# PIC18F26Q84 register map
Vendor: Microchip
Registers are 8-bit, read-write, reset 0x0 unless marked. A register's access mark holds for its fields unless they carry their own. Addresses are absolute, and some are shared; only a register's first bit layout is shown; [hi:lo] are bit positions; {n}, {i} and the like mark numbered series; 'fields as' and 'values as' point back to an identical list.

## tmr_smt
0x300 SMT1TMRL
  [7:0] TMR
0x301 SMT1TMRH
  [7:0] TMR
0x302 SMT1TMRU
  [7:0] TMR
0x303 SMT1CPRL ro reset not defined — (power-on value xxxxxxxx)
  [7:0] CPR
0x304 SMT1CPRH ro reset not defined — (power-on value xxxxxxxx)
  [7:0] CPR
0x305 SMT1CPRU ro reset not defined — (power-on value xxxxxxxx)
  [7:0] CPR
0x306 SMT1CPWL ro reset not defined — (power-on value xxxxxxxx)
  [7:0] CPW
0x307 SMT1CPWH ro reset not defined — (power-on value xxxxxxxx)
  [7:0] CPW
0x308 SMT1CPWU ro reset not defined — (power-on value xxxxxxxx)
  [7:0] CPW
0x309 SMT1PRL reset 0xFF
  [7:0] PR
0x30A SMT1PRH reset 0xFF
  [7:0] PR
0x30B SMT1PRU reset 0xFF
  [7:0] PR
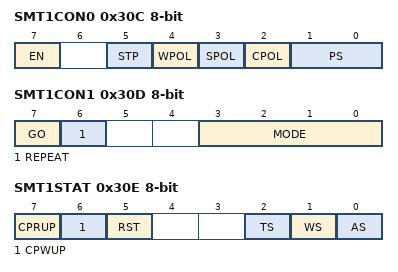
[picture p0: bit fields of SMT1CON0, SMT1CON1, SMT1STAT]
0x30C SMT1CON0
  [7] EN, [5] STP, [4] WPOL, [3] SPOL, [2] CPOL, [1:0] PS
0x30D SMT1CON1
  [7] GO, [6] REPEAT, [3:0] MODE
0x30E SMT1STAT
  [7] CPRUP, [6] CPWUP, [5] RST, [2] TS ro, [1] WS ro, [0] AS ro
0x30F SMT1CLK
  [2:0] CSEL
0x310 SMT1SIG
  [4:0] SSEL
0x311 SMT1WIN
  [4:0] WSEL

## tmr
0x318 TMR0L
0x319 TMR0H reset 0xFF
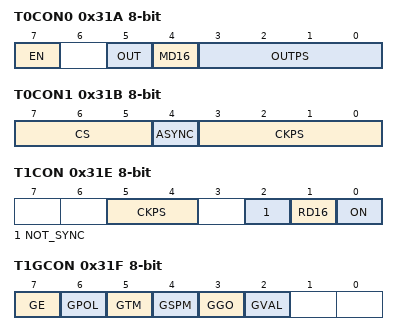
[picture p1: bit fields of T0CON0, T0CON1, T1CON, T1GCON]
0x31A T0CON0
  [7] EN, [5] OUT ro, [4] MD16, [3:0] OUTPS
0x31B T0CON1
  [7:5] CS, [4] ASYNC, [3:0] CKPS
0x31C TMR1L
0x31D TMR1H
0x31E T1CON
  [5:4] CKPS, [2] NOT_SYNC, [1] RD16, [0] ON
0x31F T1GCON reset not defined — (power-on value 00000x--)
  [7] GE, [6] GPOL, [5] GTM, [4] GSPM, [3] GGO, [2] GVAL ro
0x320 T1GATE
  [4:0] GSS
0x321 T1CLK
  [4:0] CS
0x322 T2TMR — 8-bit period timer
  [7:0] TMR2
0x323 T2PR reset 0xFF
  [7:0] PR2
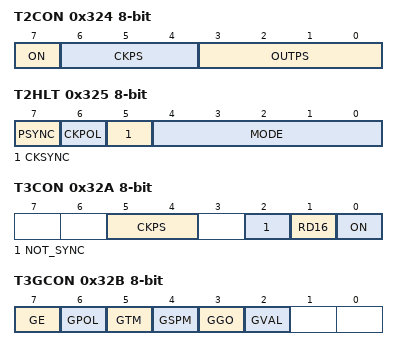
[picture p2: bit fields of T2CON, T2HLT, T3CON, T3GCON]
0x324 T2CON
  [7] ON, [6:4] CKPS, [3:0] OUTPS
0x325 T2HLT
  [7] PSYNC, [6] CKPOL, [5] CKSYNC, [4:0] MODE
0x326 T2CLKCON
  [3:0] CS
0x327 T2RST
  [4:0] RSEL
0x328 TMR3L
0x329 TMR3H
0x32A T3CON
  [5:4] CKPS, [2] NOT_SYNC, [1] RD16, [0] ON
0x32B T3GCON reset not defined — (power-on value 00000x--)
  [7] GE, [6] GPOL, [5] GTM, [4] GSPM, [3] GGO, [2] GVAL ro
0x32C T3GATE
  [4:0] GSS
0x32D T3CLK
  [4:0] CS
0x32E T4TMR — 8-bit period timer
  [7:0] TMR4
0x32F T4PR reset 0xFF
  [7:0] PR4
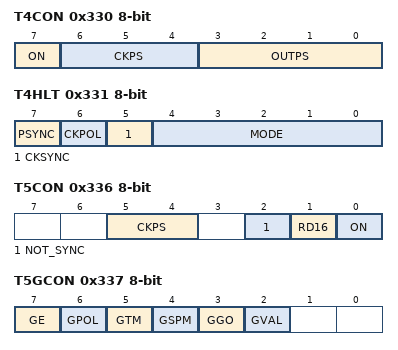
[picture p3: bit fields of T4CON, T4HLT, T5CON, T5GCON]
0x330 T4CON
  [7] ON, [6:4] CKPS, [3:0] OUTPS
0x331 T4HLT
  [7] PSYNC, [6] CKPOL, [5] CKSYNC, [4:0] MODE
0x332 T4CLKCON
  [3:0] CS
0x333 T4RST
  [4:0] RSEL
0x334 TMR5L
0x335 TMR5H
0x336 T5CON
  [5:4] CKPS, [2] NOT_SYNC, [1] RD16, [0] ON
0x337 T5GCON reset not defined — (power-on value 00000x--)
  [7] GE, [6] GPOL, [5] GTM, [4] GSPM, [3] GGO, [2] GVAL ro
0x338 T5GATE
  [4:0] GSS
0x339 T5CLK
  [4:0] CS
0x33A T6TMR — 8-bit period timer
  [7:0] TMR6
0x33B T6PR reset 0xFF
  [7:0] PR6
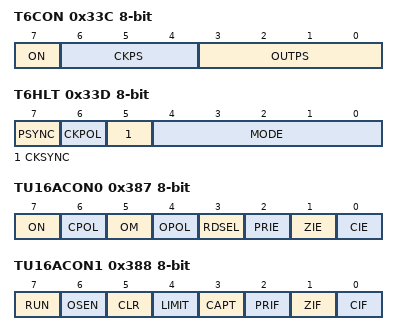
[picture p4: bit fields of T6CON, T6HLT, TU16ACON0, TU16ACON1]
0x33C T6CON
  [7] ON, [6:4] CKPS, [3:0] OUTPS
0x33D T6HLT
  [7] PSYNC, [6] CKPOL, [5] CKSYNC, [4:0] MODE
0x33E T6CLKCON
  [3:0] CS
0x33F T6RST
  [4:0] RSEL
0x387 TU16ACON0
  [7] ON, [6] CPOL, [5] OM, [4] OPOL, [3] RDSEL, [2] PRIE, [1] ZIE, [0] CIE
0x388 TU16ACON1
  [7] RUN ro, [6] OSEN, [5] CLR, [4] LIMIT, [3] CAPT, [2] PRIF, [1] ZIF, [0] CIF
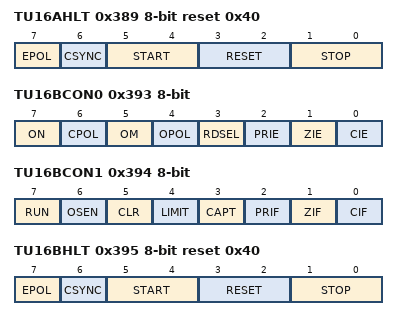
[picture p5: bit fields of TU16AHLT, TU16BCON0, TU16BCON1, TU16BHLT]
0x389 TU16AHLT reset 0x40
  [7] EPOL, [6] CSYNC, [5:4] START, [3:2] RESET, [1:0] STOP
0x38A TU16APS
  [7:0] PS
0x38D TU16APRL reset 0xFF
  [7:0] PRL
0x38E TU16APRH reset 0xFF
  [7:0] PRH
0x38F TU16ACLK
  [4:0] CLK
0x390 TU16AERS
  [5:0] ERS
0x393 TU16BCON0
  fields as TU16ACON0
0x394 TU16BCON1
  fields as TU16ACON1
0x395 TU16BHLT reset 0x40
  [7] EPOL, [6] CSYNC, [5:4] START, [3:2] RESET, [1:0] STOP
0x396 TU16BPS
  [7:0] PS
0x399 TU16BPRL reset 0xFF
  [7:0] PRL
0x39A TU16BPRH reset 0xFF
  [7:0] PRH
0x39B TU16BCLK
  [4:0] CLK
0x39C TU16BERS
  [5:0] ERS

## ccp
{0x33C+4i} CCPR{i}L reset not defined (i=1..3) — (power-on value xxxxxxxx)
  [7:0] RL
{0x33D+4i} CCPR{i}H reset not defined (i=1..3) — (power-on value xxxxxxxx)
  [7:0] RH
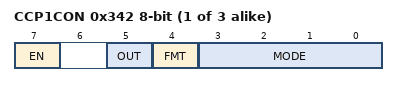
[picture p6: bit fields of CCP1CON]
{0x33E+4i} CCP{i}CON (i=1..3)
  [7] EN, [5] OUT ro, [4] FMT, [3:0] MODE
{0x33F+4i} CCP{i}CAP (i=1..3)
  [3:0] CTS

## math_progcrc
0x34F CRCDATAL
  [7:0] DATA
0x350 CRCDATAH
  [7:0] DATA
0x351 CRCDATAU
  [7:0] DATA
0x352 CRCDATAT
  [7:0] DATA
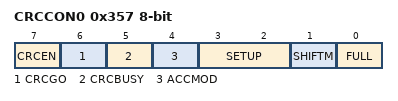
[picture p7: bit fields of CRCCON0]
0x357 CRCCON0
  [7] CRCEN, [6] CRCGO, [5] CRCBUSY ro, [4] ACCMOD, [3:2] SETUP, [1] SHIFTM, [0] FULL ro
0x358 CRCCON1
  [4:0] PLEN
0x359 CRCCON2
  [4:0] DLEN
